AUTOSAR XML (schema 4-2-2)
package /Components
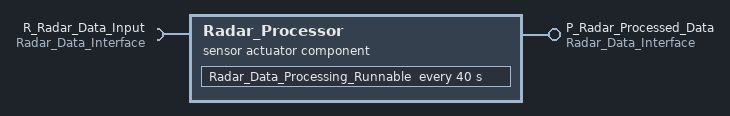
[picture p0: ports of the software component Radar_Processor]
  sensor actuator sw component type Radar_Processor
    provide port P_Radar_Processed_Data: provided-interface=Radar_Data_Interface
    require port R_Radar_Data_Input: required-interface=Radar_Data_Interface
    behavior Radar_Proc_Internal_Behavior
      data send completed event Radar_Data_Sent: start-on-event=Radar_Data_Processing_Runnable, event-source=Radar_Data_Output
      timing event Radar_Periodic_Timer: start-on-event=Radar_Data_Processing_Runnable, period=40
      runnable Radar_Data_Processing_Runnable: minimum-start-interval=1, symbol=Radar_Proc_Symbol
        data-receive-point-by-arguments:
          access Radar_Data_Input: accessed-variable=R_Radar_Data_Input.Radar_Data
        data-send-points:
          access Radar_Data_Output: accessed-variable=P_Radar_Processed_Data.Radar_Data
